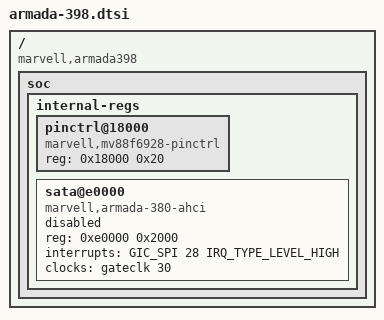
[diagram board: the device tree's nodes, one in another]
// SPDX-License-Identifier: (GPL-2.0+ OR MIT)
/*
 * Device Tree Include file for Marvell Armada 398 SoC.
 *
 * Copyright (C) 2015 Marvell
 *
 * Thomas Petazzoni <thomas.petazzoni@free-electrons.com>
 */

#include "armada-395.dtsi"

/ {
	compatible = "marvell,armada398", "marvell,armada390";

	soc {
		internal-regs {
			pinctrl@18000 {
				compatible = "marvell,mv88f6928-pinctrl";
				reg = <0x18000 0x20>;
			};

			sata@e0000 {
				compatible = "marvell,armada-380-ahci";
				reg = <0xe0000 0x2000>;
				interrupts = <GIC_SPI 28 IRQ_TYPE_LEVEL_HIGH>;
				clocks = <&gateclk 30>;
				status = "disabled";
			};
		};
	};
};
